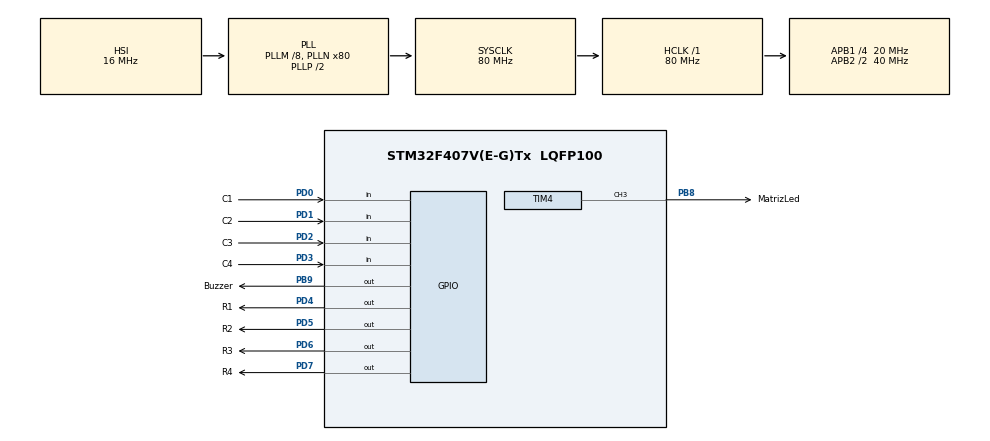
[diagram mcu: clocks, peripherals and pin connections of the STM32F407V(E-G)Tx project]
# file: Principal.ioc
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Dma.Request0=TIM4_CH3
Dma.TIM4_CH3.0.Direction=DMA_MEMORY_TO_PERIPH
Dma.TIM4_CH3.0.FIFOMode=DMA_FIFOMODE_DISABLE
Dma.TIM4_CH3.0.Instance=DMA1_Stream7
Dma.TIM4_CH3.0.MemDataAlignment=DMA_MDATAALIGN_HALFWORD
Dma.TIM4_CH3.0.MemInc=DMA_MINC_ENABLE
Dma.TIM4_CH3.0.Mode=DMA_NORMAL
Dma.TIM4_CH3.0.PeriphDataAlignment=DMA_PDATAALIGN_HALFWORD
Dma.TIM4_CH3.0.PeriphInc=DMA_PINC_DISABLE
Dma.TIM4_CH3.0.Priority=DMA_PRIORITY_HIGH
Mcu.Family=STM32F4
Mcu.Name=STM32F407V(E-G)Tx
Mcu.Package=LQFP100
NVIC.DMA1_Stream7_IRQn=true\:0\:0\:false\:false\:true\:false\:true\:true
NVIC.PriorityGroup=NVIC_PRIORITYGROUP_0
PA13.Mode=Serial_Wire
PA13.Signal=SYS_JTMS-SWDIO
PA14.Mode=Serial_Wire
PA14.Signal=SYS_JTCK-SWCLK
PB8.GPIO_Label=MatrizLed
PB8.Signal=S_TIM4_CH3
PB9.GPIO_Label=Buzzer
PB9.Signal=GPIO_Output
PD0.GPIO_Label=C1
PD0.Signal=GPIO_Input
PD1.GPIO_Label=C2
PD1.Signal=GPIO_Input
PD2.GPIO_Label=C3
PD2.Signal=GPIO_Input
PD3.GPIO_Label=C4
PD3.Signal=GPIO_Input
PD4.GPIO_Label=R1
PD4.Signal=GPIO_Output
PD5.GPIO_Label=R2
PD5.Signal=GPIO_Output
PD6.GPIO_Label=R3
PD6.Signal=GPIO_Output
PD7.GPIO_Label=R4
PD7.Signal=GPIO_Output
ProjectManager.HeapSize=0x200
ProjectManager.StackSize=0x400
ProjectManager.TargetToolchain=STM32CubeIDE
RCC.48MHZClocksFreq_Value=22857142.85714286
RCC.AHBFreq_Value=80000000
RCC.APB1CLKDivider=RCC_HCLK_DIV4
RCC.APB1Freq_Value=20000000
RCC.APB1TimFreq_Value=40000000
RCC.APB2CLKDivider=RCC_HCLK_DIV2
RCC.APB2Freq_Value=40000000
RCC.APB2TimFreq_Value=80000000
RCC.CortexFreq_Value=80000000
RCC.HCLKFreq_Value=80000000
RCC.HSE_VALUE=8000000
RCC.HSI_VALUE=16000000
RCC.LSE_VALUE=32768
RCC.PLLM=8
RCC.PLLN=80
RCC.PLLQ=7
RCC.SYSCLKFreq_VALUE=80000000
RCC.SYSCLKSource=RCC_SYSCLKSOURCE_PLLCLK
RCC.VCOOutputFreq_Value=160000000
SH.S_TIM4_CH3.0=TIM4_CH3,PWM Generation3 CH3
TIM4.Channel-PWM\ Generation3\ CH3=TIM_CHANNEL_3
TIM4.Period=49
VP_TIM4_VS_ClockSourceINT.Mode=Internal
board=STM32F407G-DISC1

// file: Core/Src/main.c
/* USER CODE BEGIN Header */
/**
 ******************************************************************************
 * @file           : main.c
 * @brief          : Main program body
 ******************************************************************************
 * @attention
 *
 * Copyright (c) 2026 STMicroelectronics.
 * All rights reserved.
 *
 * This software is licensed under terms that can be found in the LICENSE file
 * in the root directory of this software component.
 * If no LICENSE file comes with this software, it is provided AS-IS.
 *
 ******************************************************************************
 */
/* USER CODE END Header */
#include "main.h"

/* USER CODE BEGIN Includes */
#include "Teclado.h"
#include "Buzzer.h"
#include "ws2812b.h"
#include "Menu.h"
#include "Juego.h"

/* USER CODE END Includes */

TIM_HandleTypeDef htim4;
DMA_HandleTypeDef hdma_tim4_ch3;

void SystemClock_Config(void);
static void MX_GPIO_Init(void);
static void MX_DMA_Init(void);
static void MX_TIM4_Init(void);

/* USER CODE BEGIN 0 */
int modo = 0;
int seleccion = 0;
int salida = 0;
int resultado = 0;
int jugador_actual = 1;
/* USER CODE END 0 */

int main(void) {

	HAL_Init();
	SystemClock_Config();
	MX_GPIO_Init();
	MX_DMA_Init();
	MX_TIM4_Init();
	/* USER CODE BEGIN 2 */
	Inicio();
	modo = Seleccion(modo);

	while (1) {
		switch (modo) {
		case 0:
			SeleccionarColumna();
			Gravedad();
			break;
		case 1:
			SeleccionarColumna();
			Gravedad();
			break;
		}
		verificar_victoria();
		if (resultado != 0) {
			animacion_victoria(resultado);
			WS2812_RESET();
			WS2812_Manda_Trama();
			Limpiar();
			jugador_actual = 1;
			resultado = 0;
			modo = Seleccion(modo);
		}
	}
}

void SystemClock_Config(void) {
	RCC_OscInitTypeDef RCC_OscInitStruct = { 0 };
	RCC_ClkInitTypeDef RCC_ClkInitStruct = { 0 };

	/** Configure the main internal regulator output voltage
	 */
	__HAL_RCC_PWR_CLK_ENABLE();
	__HAL_PWR_VOLTAGESCALING_CONFIG(PWR_REGULATOR_VOLTAGE_SCALE1);

	/** Initializes the RCC Oscillators according to the specified parameters
	 * in the RCC_OscInitTypeDef structure.
	 */
	RCC_OscInitStruct.OscillatorType = RCC_OSCILLATORTYPE_HSI;
	RCC_OscInitStruct.HSIState = RCC_HSI_ON;
	RCC_OscInitStruct.HSICalibrationValue = RCC_HSICALIBRATION_DEFAULT;
	RCC_OscInitStruct.PLL.PLLState = RCC_PLL_ON;
	RCC_OscInitStruct.PLL.PLLSource = RCC_PLLSOURCE_HSI;
	RCC_OscInitStruct.PLL.PLLM = 8;
	RCC_OscInitStruct.PLL.PLLN = 80;
	RCC_OscInitStruct.PLL.PLLP = RCC_PLLP_DIV2;
	RCC_OscInitStruct.PLL.PLLQ = 7;
	if (HAL_RCC_OscConfig(&RCC_OscInitStruct) != HAL_OK) {
		Error_Handler();
	}

	/** Initializes the CPU, AHB and APB buses clocks
	 */
	RCC_ClkInitStruct.ClockType = RCC_CLOCKTYPE_HCLK | RCC_CLOCKTYPE_SYSCLK
			| RCC_CLOCKTYPE_PCLK1 | RCC_CLOCKTYPE_PCLK2;
	RCC_ClkInitStruct.SYSCLKSource = RCC_SYSCLKSOURCE_PLLCLK;
	RCC_ClkInitStruct.AHBCLKDivider = RCC_SYSCLK_DIV1;
	RCC_ClkInitStruct.APB1CLKDivider = RCC_HCLK_DIV4;
	RCC_ClkInitStruct.APB2CLKDivider = RCC_HCLK_DIV2;

	if (HAL_RCC_ClockConfig(&RCC_ClkInitStruct, FLASH_LATENCY_2) != HAL_OK) {
		Error_Handler();
	}
}

static void MX_TIM4_Init(void) {

	TIM_ClockConfigTypeDef sClockSourceConfig = { 0 };
	TIM_MasterConfigTypeDef sMasterConfig = { 0 };
	TIM_OC_InitTypeDef sConfigOC = { 0 };

	htim4.Instance = TIM4;
	htim4.Init.Prescaler = 0;
	htim4.Init.CounterMode = TIM_COUNTERMODE_UP;
	htim4.Init.Period = 49;
	htim4.Init.ClockDivision = TIM_CLOCKDIVISION_DIV1;
	htim4.Init.AutoReloadPreload = TIM_AUTORELOAD_PRELOAD_DISABLE;
	if (HAL_TIM_Base_Init(&htim4) != HAL_OK) {
		Error_Handler();
	}
	sClockSourceConfig.ClockSource = TIM_CLOCKSOURCE_INTERNAL;
	if (HAL_TIM_ConfigClockSource(&htim4, &sClockSourceConfig) != HAL_OK) {
		Error_Handler();
	}
	if (HAL_TIM_PWM_Init(&htim4) != HAL_OK) {
		Error_Handler();
	}
	sMasterConfig.MasterOutputTrigger = TIM_TRGO_RESET;
	sMasterConfig.MasterSlaveMode = TIM_MASTERSLAVEMODE_DISABLE;
	if (HAL_TIMEx_MasterConfigSynchronization(&htim4, &sMasterConfig)
			!= HAL_OK) {
		Error_Handler();
	}
	sConfigOC.OCMode = TIM_OCMODE_PWM1;
	sConfigOC.Pulse = 0;
	sConfigOC.OCPolarity = TIM_OCPOLARITY_HIGH;
	sConfigOC.OCFastMode = TIM_OCFAST_DISABLE;
	if (HAL_TIM_PWM_ConfigChannel(&htim4, &sConfigOC, TIM_CHANNEL_3)
			!= HAL_OK) {
		Error_Handler();
	}
	HAL_TIM_MspPostInit(&htim4);

}

static void MX_DMA_Init(void) {

	/* DMA controller clock enable */
	__HAL_RCC_DMA1_CLK_ENABLE();

	/* DMA interrupt init */
	/* DMA1_Stream7_IRQn interrupt configuration */
	HAL_NVIC_SetPriority(DMA1_Stream7_IRQn, 0, 0);
	HAL_NVIC_EnableIRQ(DMA1_Stream7_IRQn);

}

static void MX_GPIO_Init(void) {
	GPIO_InitTypeDef GPIO_InitStruct = { 0 };

	/* GPIO Ports Clock Enable */
	__HAL_RCC_GPIOA_CLK_ENABLE();
	__HAL_RCC_GPIOD_CLK_ENABLE();
	__HAL_RCC_GPIOB_CLK_ENABLE();

	/*Configure GPIO pin Output Level */
	HAL_GPIO_WritePin(GPIOD, R1_Pin | R2_Pin | R3_Pin | R4_Pin, GPIO_PIN_RESET);

	/*Configure GPIO pin Output Level */
	HAL_GPIO_WritePin(Buzzer_GPIO_Port, Buzzer_Pin, GPIO_PIN_RESET);

	/*Configure GPIO pins : C1_Pin C2_Pin C3_Pin C4_Pin */
	GPIO_InitStruct.Pin = C1_Pin | C2_Pin | C3_Pin | C4_Pin;
	GPIO_InitStruct.Mode = GPIO_MODE_INPUT;
	GPIO_InitStruct.Pull = GPIO_NOPULL;
	HAL_GPIO_Init(GPIOD, &GPIO_InitStruct);

	/*Configure GPIO pins : R1_Pin R2_Pin R3_Pin R4_Pin */
	GPIO_InitStruct.Pin = R1_Pin | R2_Pin | R3_Pin | R4_Pin;
	GPIO_InitStruct.Mode = GPIO_MODE_OUTPUT_PP;
	GPIO_InitStruct.Pull = GPIO_NOPULL;
	GPIO_InitStruct.Speed = GPIO_SPEED_FREQ_LOW;
	HAL_GPIO_Init(GPIOD, &GPIO_InitStruct);

	/*Configure GPIO pin : Buzzer_Pin */
	GPIO_InitStruct.Pin = Buzzer_Pin;
	GPIO_InitStruct.Mode = GPIO_MODE_OUTPUT_PP;
	GPIO_InitStruct.Pull = GPIO_NOPULL;
	GPIO_InitStruct.Speed = GPIO_SPEED_FREQ_LOW;
	HAL_GPIO_Init(Buzzer_GPIO_Port, &GPIO_InitStruct);

}

void Error_Handler(void) {
	__disable_irq();
	while (1) {
	}
}
